VERSION ""

NS_ :

BS_:

BU_: ECU VECTOR__XXX

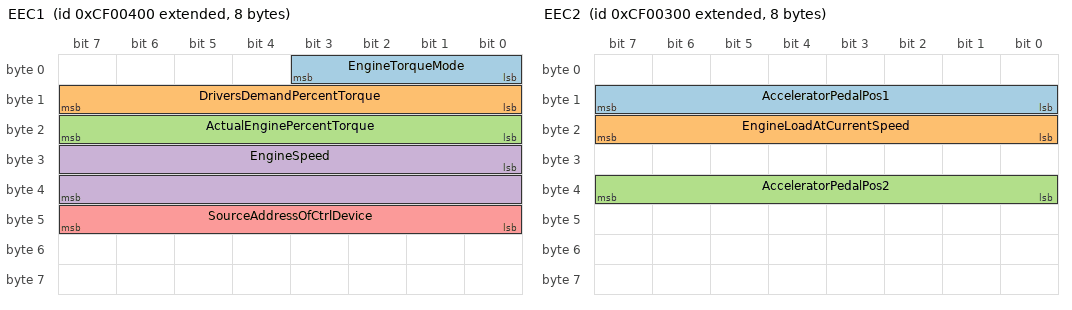
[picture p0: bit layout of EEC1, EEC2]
BO_ 2364539904 EEC1: 8 ECU
 SG_ EngineTorqueMode : 0|4@1+ (1,0) [0|15] "" Vector__XXX
 SG_ DriversDemandPercentTorque : 8|8@1- (1,-125) [-125|125] "%" Vector__XXX
 SG_ ActualEnginePercentTorque : 16|8@1- (1,-125) [-125|125] "%" Vector__XXX
 SG_ EngineSpeed : 24|16@1+ (0.125,0) [0|8031.875] "rpm" Vector__XXX
 SG_ SourceAddressOfCtrlDevice : 40|8@1+ (1,0) [0|255] "" Vector__XXX

BO_ 2364539648 EEC2: 8 ECU
 SG_ AcceleratorPedalPos1 : 8|8@1+ (0.4,0) [0|100] "%" Vector__XXX
 SG_ EngineLoadAtCurrentSpeed : 16|8@1+ (1,0) [0|250] "%" Vector__XXX
 SG_ AcceleratorPedalPos2 : 32|8@1+ (0.4,0) [0|100] "%" Vector__XXX

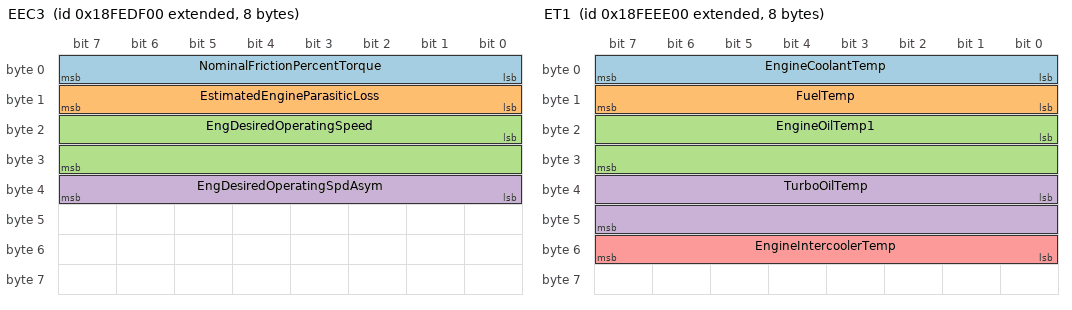
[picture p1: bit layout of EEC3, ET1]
BO_ 2566840064 EEC3: 8 ECU
 SG_ NominalFrictionPercentTorque : 0|8@1- (1,-125) [-125|125] "%" Vector__XXX
 SG_ EstimatedEngineParasiticLoss : 8|8@1- (1,-125) [-125|125] "%" Vector__XXX
 SG_ EngDesiredOperatingSpeed : 16|16@1+ (0.125,0) [0|8031.875] "rpm" Vector__XXX
 SG_ EngDesiredOperatingSpdAsym : 32|8@1+ (0.125,0) [0|31.875] "%" Vector__XXX

BO_ 2566843904 ET1: 8 ECU
 SG_ EngineCoolantTemp : 0|8@1+ (1,-40) [-40|210] "degC" Vector__XXX
 SG_ FuelTemp : 8|8@1+ (1,-40) [-40|210] "degC" Vector__XXX
 SG_ EngineOilTemp1 : 16|16@1+ (0.03125,-273) [-273|1735] "degC" Vector__XXX
 SG_ TurboOilTemp : 32|16@1+ (0.03125,-273) [-273|1735] "degC" Vector__XXX
 SG_ EngineIntercoolerTemp : 48|8@1+ (1,-40) [-40|210] "degC" Vector__XXX

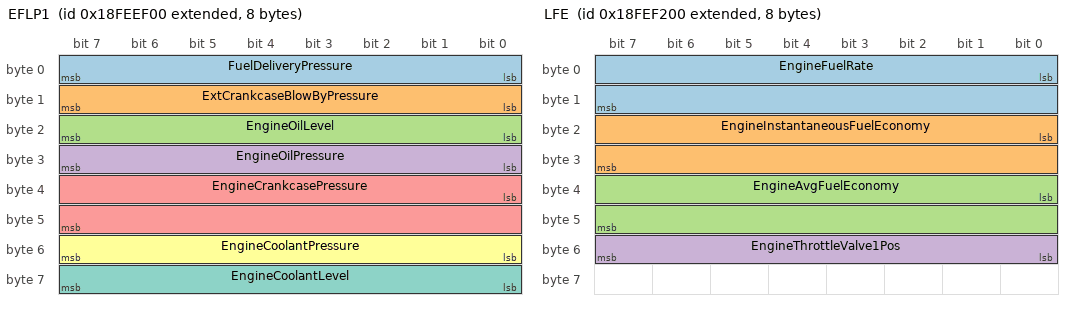
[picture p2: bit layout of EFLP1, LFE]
BO_ 2566844160 EFLP1: 8 ECU
 SG_ FuelDeliveryPressure : 0|8@1+ (4,0) [0|1000] "kPa" Vector__XXX
 SG_ ExtCrankcaseBlowByPressure : 8|8@1+ (0.5,0) [0|125] "kPa" Vector__XXX
 SG_ EngineOilLevel : 16|8@1+ (0.4,0) [0|100] "%" Vector__XXX
 SG_ EngineOilPressure : 24|8@1+ (4,0) [0|1000] "kPa" Vector__XXX
 SG_ EngineCrankcasePressure : 32|16@1- (0.0078125,-250) [-250|251] "kPa" Vector__XXX
 SG_ EngineCoolantPressure : 48|8@1+ (2,0) [0|500] "kPa" Vector__XXX
 SG_ EngineCoolantLevel : 56|8@1+ (0.4,0) [0|100] "%" Vector__XXX

BO_ 2566844928 LFE: 8 ECU
 SG_ EngineFuelRate : 0|16@1+ (0.05,0) [0|3212.75] "L/h" Vector__XXX
 SG_ EngineInstantaneousFuelEconomy : 16|16@1+ (0.001953125,0) [0|125.5] "km/L" Vector__XXX
 SG_ EngineAvgFuelEconomy : 32|16@1+ (0.001953125,0) [0|125.5] "km/L" Vector__XXX
 SG_ EngineThrottleValve1Pos : 48|8@1+ (0.4,0) [0|100] "%" Vector__XXX

BO_ 2566841600 EngineHoursRevolutions: 8 ECU
 SG_ EngineTotalHoursOfOperation : 0|32@1+ (0.05,0) [0|210554060.75] "hr" Vector__XXX
 SG_ EngineTotalRevolutions : 32|32@1+ (1000,0) [0|4211081215000] "r" Vector__XXX

BO_ 2566846720 LFC: 8 ECU
 SG_ EngineTripFuel : 0|32@1+ (0.5,0) [0|2105540607.5] "L" Vector__XXX
 SG_ EngineTotalFuelUsed : 32|32@1+ (0.5,0) [0|2105540607.5] "L" Vector__XXX

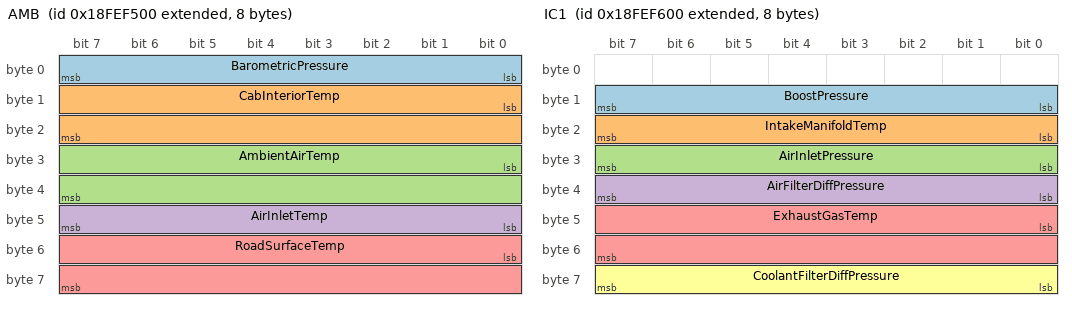
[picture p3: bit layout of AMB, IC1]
BO_ 2566845696 AMB: 8 ECU
 SG_ BarometricPressure : 0|8@1+ (0.5,0) [0|125] "kPa" Vector__XXX
 SG_ CabInteriorTemp : 8|16@1+ (0.03125,-273) [-273|1735] "degC" Vector__XXX
 SG_ AmbientAirTemp : 24|16@1+ (0.03125,-273) [-273|1735] "degC" Vector__XXX
 SG_ AirInletTemp : 40|8@1+ (1,-40) [-40|210] "degC" Vector__XXX
 SG_ RoadSurfaceTemp : 48|16@1+ (0.03125,-273) [-273|1735] "degC" Vector__XXX

BO_ 2566845952 IC1: 8 ECU
 SG_ BoostPressure : 8|8@1+ (2,0) [0|500] "kPa" Vector__XXX
 SG_ IntakeManifoldTemp : 16|8@1+ (1,-40) [-40|210] "degC" Vector__XXX
 SG_ AirInletPressure : 24|8@1+ (2,0) [0|500] "kPa" Vector__XXX
 SG_ AirFilterDiffPressure : 32|8@1+ (0.05,0) [0|12.5] "kPa" Vector__XXX
 SG_ ExhaustGasTemp : 40|16@1+ (0.03125,-273) [-273|1735] "degC" Vector__XXX
 SG_ CoolantFilterDiffPressure : 56|8@1+ (0.5,0) [0|125] "kPa" Vector__XXX

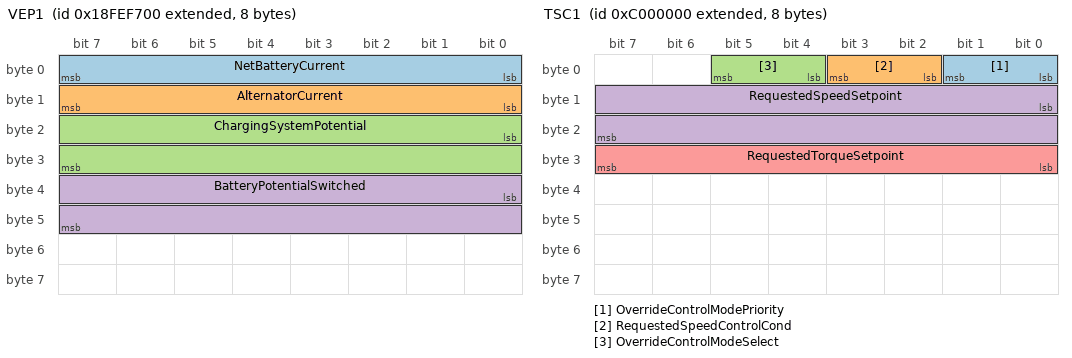
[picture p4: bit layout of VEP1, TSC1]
BO_ 2566846208 VEP1: 8 ECU
 SG_ NetBatteryCurrent : 0|8@1- (1,-125) [-125|125] "A" Vector__XXX
 SG_ AlternatorCurrent : 8|8@1+ (1,0) [0|250] "A" Vector__XXX
 SG_ ChargingSystemPotential : 16|16@1+ (0.05,0) [0|3212.75] "V" Vector__XXX
 SG_ BatteryPotentialSwitched : 32|16@1+ (0.05,0) [0|3212.75] "V" Vector__XXX

BO_ 2348810240 TSC1: 8 ECU
 SG_ OverrideControlModePriority : 0|2@1+ (1,0) [0|3] "" Vector__XXX
 SG_ RequestedSpeedControlCond : 2|2@1+ (1,0) [0|3] "" Vector__XXX
 SG_ OverrideControlModeSelect : 4|2@1+ (1,0) [0|3] "" Vector__XXX
 SG_ RequestedSpeedSetpoint : 8|16@1+ (0.125,0) [0|8031.875] "rpm" Vector__XXX
 SG_ RequestedTorqueSetpoint : 24|8@1- (1,-125) [-125|125] "%" Vector__XXX

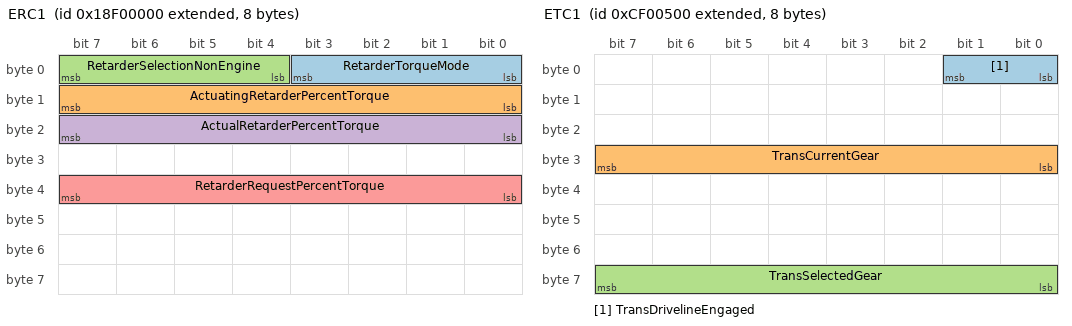
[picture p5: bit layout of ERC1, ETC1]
BO_ 2565865472 ERC1: 8 ECU
 SG_ RetarderTorqueMode : 0|4@1+ (1,0) [0|15] "" Vector__XXX
 SG_ ActuatingRetarderPercentTorque : 8|8@1- (1,-125) [-125|125] "%" Vector__XXX
 SG_ RetarderSelectionNonEngine : 4|4@1+ (1,0) [0|15] "" Vector__XXX
 SG_ ActualRetarderPercentTorque : 16|8@1- (1,-125) [-125|125] "%" Vector__XXX
 SG_ RetarderRequestPercentTorque : 32|8@1- (1,-125) [-125|125] "%" Vector__XXX

BO_ 2364540160 ETC1: 8 ECU
 SG_ TransDrivelineEngaged : 0|2@1+ (1,0) [0|3] "" Vector__XXX
 SG_ TransCurrentGear : 24|8@1- (1,-125) [-125|125] "" Vector__XXX
 SG_ TransSelectedGear : 56|8@1- (1,-125) [-125|125] "" Vector__XXX

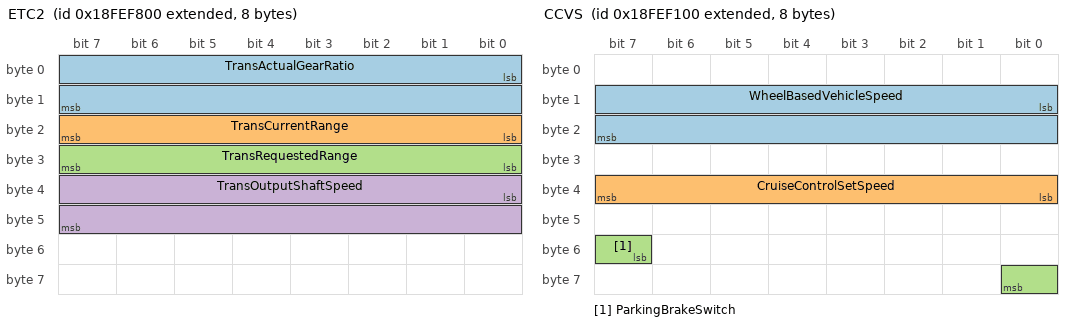
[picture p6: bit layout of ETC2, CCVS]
BO_ 2566846464 ETC2: 8 ECU
 SG_ TransActualGearRatio : 0|16@1+ (0.001,0) [0|64.255] "" Vector__XXX
 SG_ TransCurrentRange : 16|8@1+ (1,0) [0|255] "" Vector__XXX
 SG_ TransRequestedRange : 24|8@1+ (1,0) [0|255] "" Vector__XXX
 SG_ TransOutputShaftSpeed : 32|16@1+ (0.125,0) [0|8031.875] "rpm" Vector__XXX

BO_ 2566844672 CCVS: 8 ECU
 SG_ WheelBasedVehicleSpeed : 8|16@1+ (0.00390625,0) [0|250.996] "km/h" Vector__XXX
 SG_ CruiseControlSetSpeed : 32|8@1+ (1,0) [0|250] "km/h" Vector__XXX
 SG_ ParkingBrakeSwitch : 55|2@1+ (1,0) [0|3] "" Vector__XXX

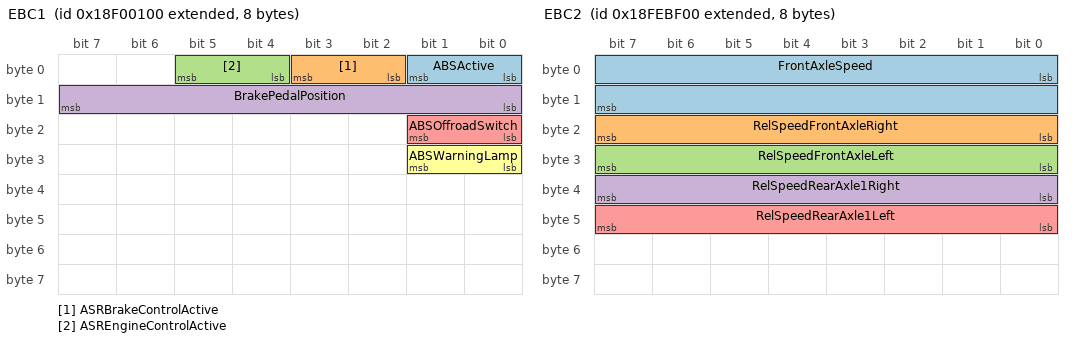
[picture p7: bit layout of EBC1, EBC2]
BO_ 2565865728 EBC1: 8 ECU
 SG_ ABSActive : 0|2@1+ (1,0) [0|3] "" Vector__XXX
 SG_ ASRBrakeControlActive : 2|2@1+ (1,0) [0|3] "" Vector__XXX
 SG_ ASREngineControlActive : 4|2@1+ (1,0) [0|3] "" Vector__XXX
 SG_ BrakePedalPosition : 8|8@1+ (0.4,0) [0|100] "%" Vector__XXX
 SG_ ABSOffroadSwitch : 16|2@1+ (1,0) [0|3] "" Vector__XXX
 SG_ ABSWarningLamp : 24|2@1+ (1,0) [0|3] "" Vector__XXX

BO_ 2566831872 EBC2: 8 ECU
 SG_ FrontAxleSpeed : 0|16@1+ (0.00390625,0) [0|250.996] "km/h" Vector__XXX
 SG_ RelSpeedFrontAxleRight : 16|8@1- (0.0625,-7.9375) [-7.9375|7.9375] "km/h" Vector__XXX
 SG_ RelSpeedFrontAxleLeft : 24|8@1- (0.0625,-7.9375) [-7.9375|7.9375] "km/h" Vector__XXX
 SG_ RelSpeedRearAxle1Right : 32|8@1- (0.0625,-7.9375) [-7.9375|7.9375] "km/h" Vector__XXX
 SG_ RelSpeedRearAxle1Left : 40|8@1- (0.0625,-7.9375) [-7.9375|7.9375] "km/h" Vector__XXX

BO_ 2566832384 VD: 8 ECU
 SG_ TripDistance : 0|32@1+ (0.125,0) [0|526385151.9] "km" Vector__XXX
 SG_ TotalVehicleDistance : 32|32@1+ (0.125,0) [0|526385151.9] "km" Vector__XXX

BO_ 2566847488 DD: 8 ECU
 SG_ WasherFluidLevel : 48|8@1+ (0.4,0) [0|100] "%" Vector__XXX
 SG_ FuelLevel1 : 56|8@1+ (0.4,0) [0|100] "%" Vector__XXX

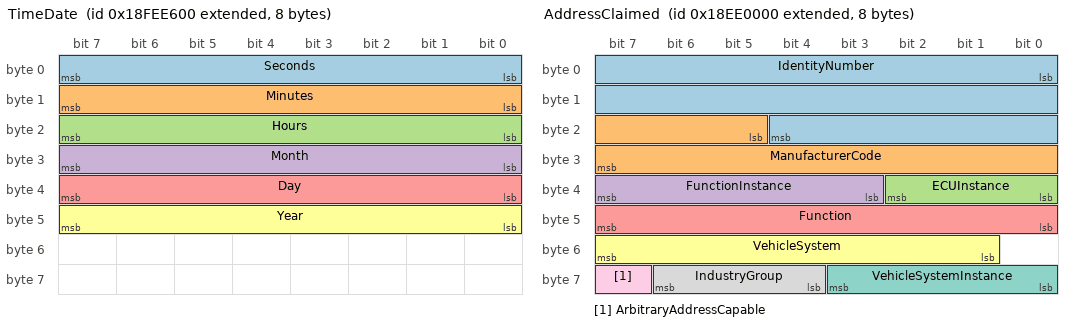
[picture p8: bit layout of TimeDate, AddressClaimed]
BO_ 2566841856 TimeDate: 8 ECU
 SG_ Seconds : 0|8@1+ (0.25,0) [0|62.75] "s" Vector__XXX
 SG_ Minutes : 8|8@1+ (1,0) [0|60] "min" Vector__XXX
 SG_ Hours : 16|8@1+ (1,0) [0|23] "hr" Vector__XXX
 SG_ Month : 24|8@1+ (1,0) [1|12] "" Vector__XXX
 SG_ Day : 32|8@1+ (0.25,0) [0|63.75] "" Vector__XXX
 SG_ Year : 40|8@1+ (1,1985) [1985|2235] "" Vector__XXX

BO_ 2565734400 AddressClaimed: 8 ECU
 SG_ IdentityNumber : 0|21@1+ (1,0) [0|2097151] "" Vector__XXX
 SG_ ManufacturerCode : 21|11@1+ (1,0) [0|2047] "" Vector__XXX
 SG_ ECUInstance : 32|3@1+ (1,0) [0|7] "" Vector__XXX
 SG_ FunctionInstance : 35|5@1+ (1,0) [0|31] "" Vector__XXX
 SG_ Function : 40|8@1+ (1,0) [0|255] "" Vector__XXX
 SG_ VehicleSystem : 49|7@1+ (1,0) [0|127] "" Vector__XXX
 SG_ VehicleSystemInstance : 56|4@1+ (1,0) [0|15] "" Vector__XXX
 SG_ IndustryGroup : 60|3@1+ (1,0) [0|7] "" Vector__XXX
 SG_ ArbitraryAddressCapable : 63|1@1+ (1,0) [0|1] "" Vector__XXX

BO_ 2565537536 RQST: 3 ECU
 SG_ RequestedPGN : 0|24@1+ (1,0) [0|16777215] "" Vector__XXX

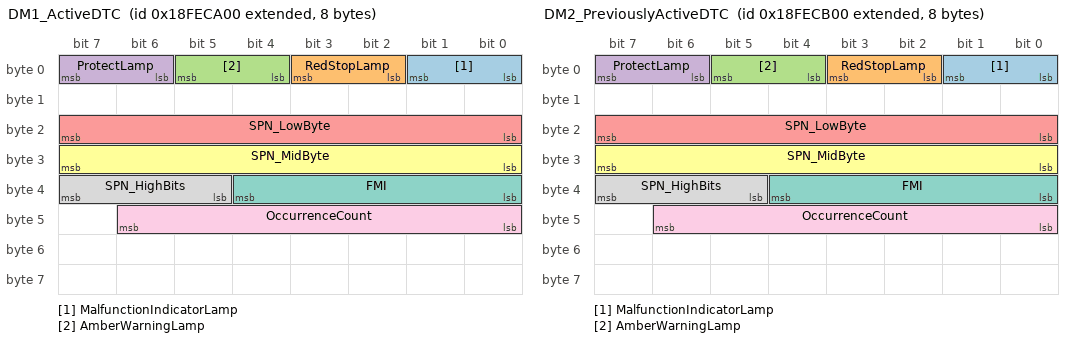
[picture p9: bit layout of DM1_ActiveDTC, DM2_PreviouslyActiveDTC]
BO_ 2566834688 DM1_ActiveDTC: 8 ECU
 SG_ MalfunctionIndicatorLamp : 0|2@1+ (1,0) [0|3] "" Vector__XXX
 SG_ RedStopLamp : 2|2@1+ (1,0) [0|3] "" Vector__XXX
 SG_ AmberWarningLamp : 4|2@1+ (1,0) [0|3] "" Vector__XXX
 SG_ ProtectLamp : 6|2@1+ (1,0) [0|3] "" Vector__XXX
 SG_ SPN_LowByte : 16|8@1+ (1,0) [0|255] "" Vector__XXX
 SG_ SPN_MidByte : 24|8@1+ (1,0) [0|255] "" Vector__XXX
 SG_ FMI : 32|5@1+ (1,0) [0|31] "" Vector__XXX
 SG_ SPN_HighBits : 37|3@1+ (1,0) [0|7] "" Vector__XXX
 SG_ OccurrenceCount : 40|7@1+ (1,0) [0|126] "" Vector__XXX

BO_ 2566834944 DM2_PreviouslyActiveDTC: 8 ECU
 SG_ MalfunctionIndicatorLamp : 0|2@1+ (1,0) [0|3] "" Vector__XXX
 SG_ RedStopLamp : 2|2@1+ (1,0) [0|3] "" Vector__XXX
 SG_ AmberWarningLamp : 4|2@1+ (1,0) [0|3] "" Vector__XXX
 SG_ ProtectLamp : 6|2@1+ (1,0) [0|3] "" Vector__XXX
 SG_ SPN_LowByte : 16|8@1+ (1,0) [0|255] "" Vector__XXX
 SG_ SPN_MidByte : 24|8@1+ (1,0) [0|255] "" Vector__XXX
 SG_ FMI : 32|5@1+ (1,0) [0|31] "" Vector__XXX
 SG_ SPN_HighBits : 37|3@1+ (1,0) [0|7] "" Vector__XXX
 SG_ OccurrenceCount : 40|7@1+ (1,0) [0|126] "" Vector__XXX

CM_ BO_ 2364539904 "[Powertrain] Broadcast message (PDU2), SA assumed 0x00 - edit to match your captured source address.";
CM_ BO_ 2364539648 "[Powertrain] Broadcast message (PDU2), SA assumed 0x00 - edit to match your captured source address.";
CM_ BO_ 2566840064 "[Powertrain] Broadcast message (PDU2), SA assumed 0x00 - edit to match your captured source address.";
CM_ BO_ 2566843904 "[Powertrain] Broadcast message (PDU2), SA assumed 0x00 - edit to match your captured source address.";
CM_ BO_ 2566844160 "[Powertrain] Broadcast message (PDU2), SA assumed 0x00 - edit to match your captured source address.";
CM_ BO_ 2566844928 "[Powertrain] Broadcast message (PDU2), SA assumed 0x00 - edit to match your captured source address.";
CM_ BO_ 2566841600 "[Powertrain] Broadcast message (PDU2), SA assumed 0x00 - edit to match your captured source address.";
CM_ BO_ 2566846720 "[Powertrain] Broadcast message (PDU2), SA assumed 0x00 - edit to match your captured source address.";
CM_ BO_ 2566845696 "[Powertrain] Broadcast message (PDU2), SA assumed 0x00 - edit to match your captured source address.";
CM_ BO_ 2566845952 "[Powertrain] Broadcast message (PDU2), SA assumed 0x00 - edit to match your captured source address.";
CM_ BO_ 2566846208 "[Powertrain] Broadcast message (PDU2), SA assumed 0x00 - edit to match your captured source address.";
CM_ BO_ 2348810240 "[Control] DESTINATION-SPECIFIC (PDU1). ID shown targets DA=0x00 (typical primary engine controller) from SA=0x00 (placeholder requesting device). For PTO speed control, DA must be set to whichever ECU actually governs the PTO engagement/speed function on your specific truck (often the engine ECU, but can be a body builder module) -- confirm from your Freightliner docs before assuming DA=0x00 is correct for PTO on a given platform.";
CM_ BO_ 2565865472 "[Control] Broadcast message (PDU2), SA assumed 0x00 - edit to match your captured source address.";
CM_ BO_ 2364540160 "[Transmission] Broadcast message (PDU2), SA assumed 0x00 - edit to match your captured source address.";
CM_ BO_ 2566846464 "[Transmission] Broadcast message (PDU2), SA assumed 0x00 - edit to match your captured source address.";
CM_ BO_ 2566844672 "[Chassis] Broadcast message (PDU2), SA assumed 0x00 - edit to match your captured source address.";
CM_ BO_ 2565865728 "[Chassis] Broadcast message (PDU2), SA assumed 0x00 - edit to match your captured source address.";
CM_ BO_ 2566831872 "[Chassis] Broadcast message (PDU2), SA assumed 0x00 - edit to match your captured source address.";
CM_ BO_ 2566832384 "[Chassis] Broadcast message (PDU2), SA assumed 0x00 - edit to match your captured source address.";
CM_ BO_ 2566847488 "[Cabin] Broadcast message (PDU2), SA assumed 0x00 - edit to match your captured source address.";
CM_ BO_ 2566841856 "[Cabin] Broadcast message (PDU2), SA assumed 0x00 - edit to match your captured source address.";
CM_ BO_ 2565734400 "[NetworkMgmt] Broadcast message (PDU2), SA assumed 0x00 - edit to match your captured source address.";
CM_ BO_ 2565537536 "[NetworkMgmt] DESTINATION-SPECIFIC (PDU1). ID shown targets DA=0xFF (global request, any node may respond). Set DA to a specific node's SA to request a PGN from that ECU only. 3-byte payload = the PGN being requested, LSB first.";
CM_ BO_ 2566834688 "[Diagnostics] Broadcast message (PDU2), SA assumed 0x00 - edit to match your captured source address.";
CM_ BO_ 2566834944 "[Diagnostics] Broadcast message (PDU2), SA assumed 0x00 - edit to match your captured source address.";
